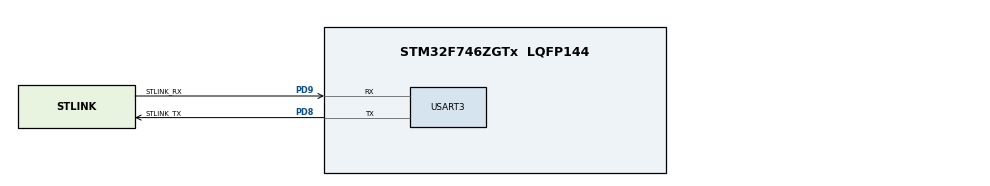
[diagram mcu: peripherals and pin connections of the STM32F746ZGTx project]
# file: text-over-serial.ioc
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CORTEX_M7.default_mode_Activation=1
Mcu.Family=STM32F7
Mcu.Name=STM32F746ZGTx
Mcu.Package=LQFP144
NVIC.PriorityGroup=NVIC_PRIORITYGROUP_4
NVIC.USART3_IRQn=true\:0\:0\:false\:false\:true\:true\:true\:true
PD8.GPIO_Label=STLINK_TX
PD8.Mode=Asynchronous
PD8.Signal=USART3_TX
PD9.GPIO_Label=STLINK_RX
PD9.Mode=Asynchronous
PD9.Signal=USART3_RX
ProjectManager.HeapSize=0x200
ProjectManager.StackSize=0x400
ProjectManager.TargetToolchain=STM32CubeIDE
RCC.HSE_VALUE=25000000
RCC.HSI_VALUE=16000000
RCC.LSE_VALUE=32768
RCC.USBFreq_Value=96000000
RCC.VCOOutputFreq_Value=192000000
USART3.VirtualMode-Asynchronous=VM_ASYNC
board=custom

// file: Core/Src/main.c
/* USER CODE BEGIN Header */
/**
  ******************************************************************************
  * @file           : main.c
  * @brief          : Main program body
  ******************************************************************************
  * @attention
  *
  * Copyright (c) 2024 STMicroelectronics.
  * All rights reserved.
  *
  * This software is licensed under terms that can be found in the LICENSE file
  * in the root directory of this software component.
  * If no LICENSE file comes with this software, it is provided AS-IS.
  *
  ******************************************************************************
  */
/* USER CODE END Header */
#include "main.h"

UART_HandleTypeDef huart3;

void SystemClock_Config(void);
static void MPU_Config(void);
static void MX_GPIO_Init(void);
static void MX_USART3_UART_Init(void);

/* USER CODE BEGIN 0 */
char msg[] = "hello, world! abcdefgheijklmnoptkqjfqlkjfqlkdfjqsldkjqsdlkqsjdqlsk qfqjkqf qfq sfqsf \r\n";
char done[] = "done\r\n";
/* USER CODE END 0 */

int main(void)
{

  /* MPU Configuration--------------------------------------------------------*/
  MPU_Config();

  /* MCU Configuration--------------------------------------------------------*/

  /* Reset of all peripherals, Initializes the Flash interface and the Systick. */
  HAL_Init();

  /* Configure the system clock */
  SystemClock_Config();

  /* Initialize all configured peripherals */
  MX_GPIO_Init();
  MX_USART3_UART_Init();

  /* Infinite loop */
  while (1)
  {
	HAL_UART_Transmit_IT(&huart3, msg, sizeof(msg));
	HAL_UART_Transmit_IT(&huart3, msg, sizeof(msg));
	HAL_UART_Transmit_IT(&huart3, msg, sizeof(msg));
	HAL_UART_Transmit_IT(&huart3, msg, sizeof(msg));
	HAL_UART_Transmit_IT(&huart3, msg, sizeof(msg));
  }
}

void SystemClock_Config(void)
{
  RCC_OscInitTypeDef RCC_OscInitStruct = {0};
  RCC_ClkInitTypeDef RCC_ClkInitStruct = {0};

  /** Configure the main internal regulator output voltage
  */
  __HAL_RCC_PWR_CLK_ENABLE();
  __HAL_PWR_VOLTAGESCALING_CONFIG(PWR_REGULATOR_VOLTAGE_SCALE3);

  /** Initializes the RCC Oscillators according to the specified parameters
  * in the RCC_OscInitTypeDef structure.
  */
  RCC_OscInitStruct.OscillatorType = RCC_OSCILLATORTYPE_HSI;
  RCC_OscInitStruct.HSIState = RCC_HSI_ON;
  RCC_OscInitStruct.HSICalibrationValue = RCC_HSICALIBRATION_DEFAULT;
  RCC_OscInitStruct.PLL.PLLState = RCC_PLL_NONE;
  if (HAL_RCC_OscConfig(&RCC_OscInitStruct) != HAL_OK)
  {
    Error_Handler();
  }

  /** Initializes the CPU, AHB and APB buses clocks
  */
  RCC_ClkInitStruct.ClockType = RCC_CLOCKTYPE_HCLK|RCC_CLOCKTYPE_SYSCLK
                              |RCC_CLOCKTYPE_PCLK1|RCC_CLOCKTYPE_PCLK2;
  RCC_ClkInitStruct.SYSCLKSource = RCC_SYSCLKSOURCE_HSI;
  RCC_ClkInitStruct.AHBCLKDivider = RCC_SYSCLK_DIV1;
  RCC_ClkInitStruct.APB1CLKDivider = RCC_HCLK_DIV1;
  RCC_ClkInitStruct.APB2CLKDivider = RCC_HCLK_DIV1;

  if (HAL_RCC_ClockConfig(&RCC_ClkInitStruct, FLASH_LATENCY_0) != HAL_OK)
  {
    Error_Handler();
  }
}

static void MX_USART3_UART_Init(void)
{

  huart3.Instance = USART3;
  huart3.Init.BaudRate = 115200;
  huart3.Init.WordLength = UART_WORDLENGTH_8B;
  huart3.Init.StopBits = UART_STOPBITS_1;
  huart3.Init.Parity = UART_PARITY_NONE;
  huart3.Init.Mode = UART_MODE_TX_RX;
  huart3.Init.HwFlowCtl = UART_HWCONTROL_NONE;
  huart3.Init.OverSampling = UART_OVERSAMPLING_16;
  huart3.Init.OneBitSampling = UART_ONE_BIT_SAMPLE_DISABLE;
  huart3.AdvancedInit.AdvFeatureInit = UART_ADVFEATURE_NO_INIT;
  if (HAL_UART_Init(&huart3) != HAL_OK)
  {
    Error_Handler();
  }

}

static void MX_GPIO_Init(void)
{

  /* GPIO Ports Clock Enable */
  __HAL_RCC_GPIOD_CLK_ENABLE();

}

/* USER CODE BEGIN 4 */

void HAL_UART_TxCpltCallback (UART_HandleTypeDef *huart)
{
	HAL_UART_Transmit(&huart3, done, sizeof(done), 0xFFFF);
}

/* USER CODE END 4 */

 /* MPU Configuration */

void MPU_Config(void)
{
  MPU_Region_InitTypeDef MPU_InitStruct = {0};

  /* Disables the MPU */
  HAL_MPU_Disable();

  /** Initializes and configures the Region and the memory to be protected
  */
  MPU_InitStruct.Enable = MPU_REGION_ENABLE;
  MPU_InitStruct.Number = MPU_REGION_NUMBER0;
  MPU_InitStruct.BaseAddress = 0x0;
  MPU_InitStruct.Size = MPU_REGION_SIZE_4GB;
  MPU_InitStruct.SubRegionDisable = 0x87;
  MPU_InitStruct.TypeExtField = MPU_TEX_LEVEL0;
  MPU_InitStruct.AccessPermission = MPU_REGION_NO_ACCESS;
  MPU_InitStruct.DisableExec = MPU_INSTRUCTION_ACCESS_DISABLE;
  MPU_InitStruct.IsShareable = MPU_ACCESS_SHAREABLE;
  MPU_InitStruct.IsCacheable = MPU_ACCESS_NOT_CACHEABLE;
  MPU_InitStruct.IsBufferable = MPU_ACCESS_NOT_BUFFERABLE;

  HAL_MPU_ConfigRegion(&MPU_InitStruct);
  /* Enables the MPU */
  HAL_MPU_Enable(MPU_PRIVILEGED_DEFAULT);

}

void Error_Handler(void)
{
  __disable_irq();
  while (1)
  {
  }
}
